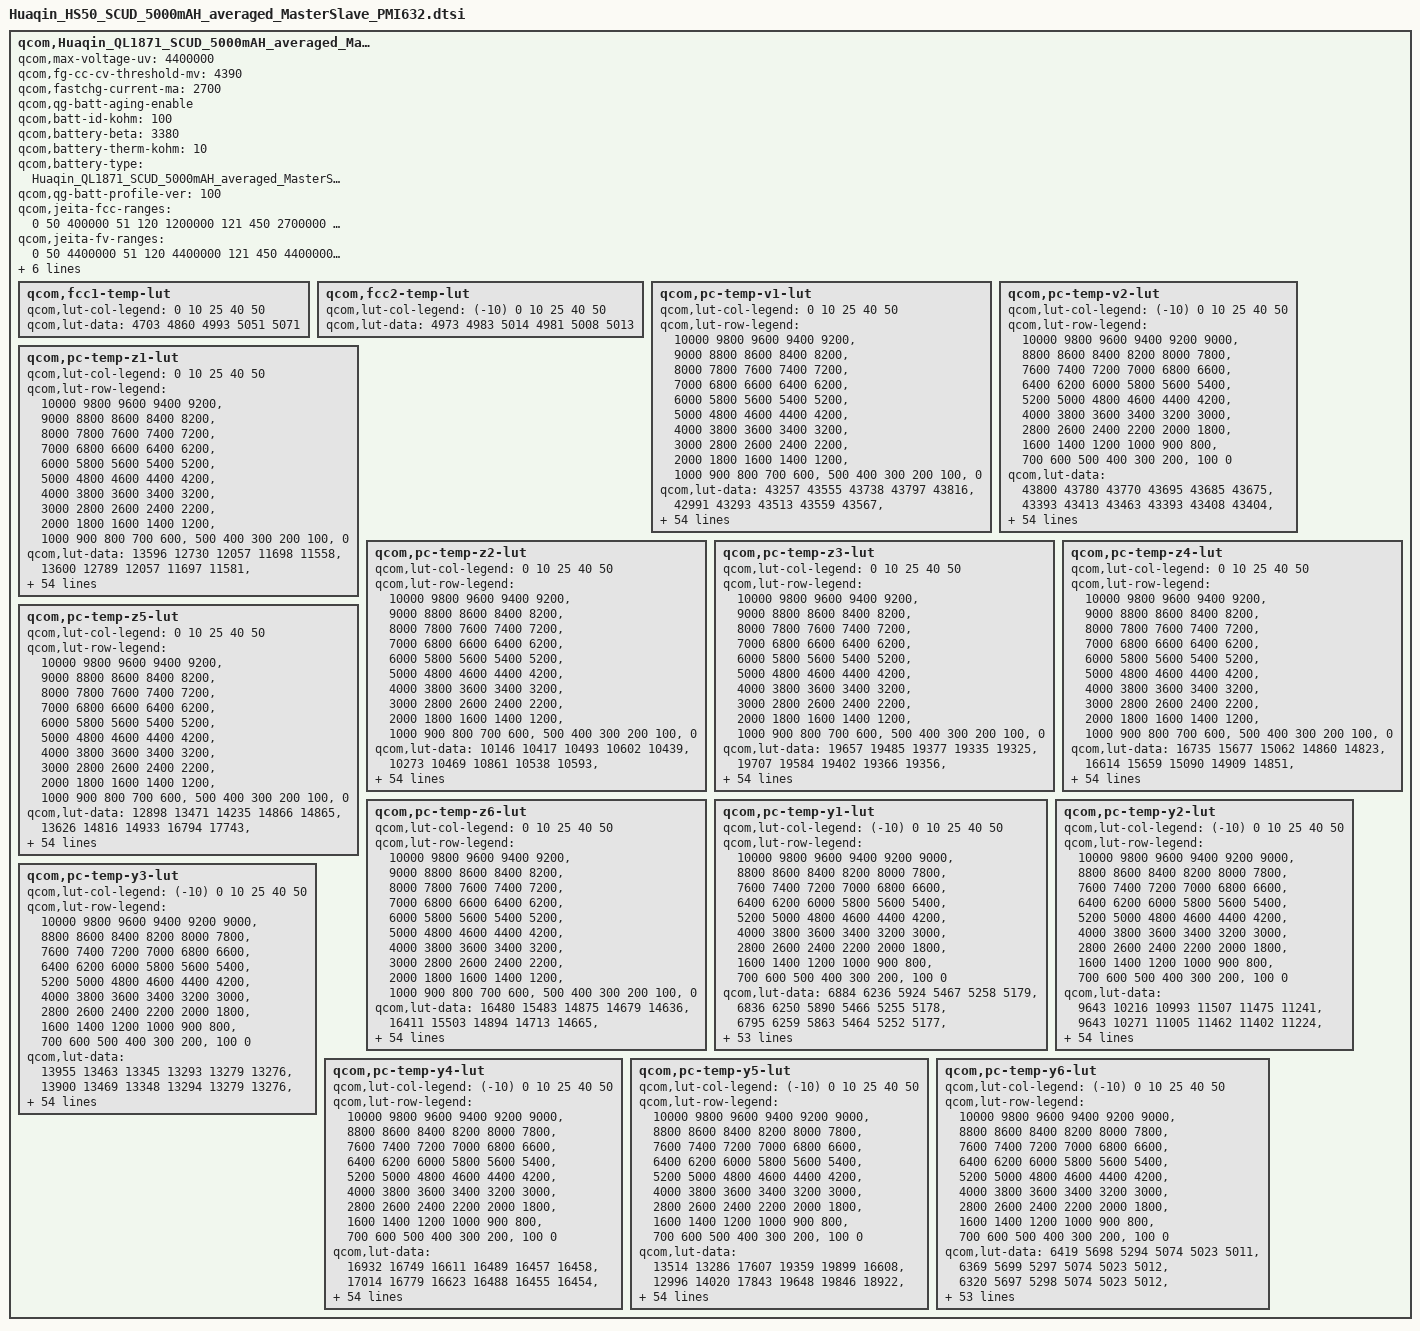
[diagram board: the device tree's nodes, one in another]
qcom,Huaqin_QL1871_SCUD_5000mAH_averaged_MasterSlave_PMI632 {
        /* Huaqin_QL1871_SCUD_5000mAH_averaged_MasterSlave_PMI632 */
	qcom,max-voltage-uv = <4400000>;
	qcom,fg-cc-cv-threshold-mv = <4390>;
	qcom,fastchg-current-ma = <2700>;
	/* HS60 add for SR-ZQL1695-01-357 Import battery aging by gaochao at 2019/08/29 start */
	qcom,qg-batt-aging-enable;
	/* HS60 add for SR-ZQL1695-01-357 Import battery aging by gaochao at 2019/08/29 end */
	qcom,batt-id-kohm = <100>;
	qcom,battery-beta = <3380>;
	qcom,battery-therm-kohm = <10>;
	qcom,battery-type = "Huaqin_QL1871_SCUD_5000mAH_averaged_MasterSlave_PMI632";
	qcom,qg-batt-profile-ver = <100>;

	qcom,jeita-fcc-ranges = <0   50   400000
				 51   120   1200000
				 121 450  2700000
				 451 500  2200000>;
	qcom,jeita-fv-ranges =  <0   50  4400000
				 51   120  4400000
				 121 450  4400000
				 451 500  4200000>;

	/* HS60 add for SR-ZQL1695-01-357 Import battery aging by gaochao at 2019/08/29 start */
	qcom,vfloat-ranges = <0 299 4400000
	                      300 399 4380000
                              400 699 4360000
                              700 999 4340000
                              1000 9999 4290000>;

	qcom,vbat-rechg-ranges = <0 299 4330000
                                  300 399 4310000
                                  400 699 4290000
                                  700 999 4270000
                                  1000 9999 4220000>;
	/* HS60 add for SR-ZQL1695-01-357 Import battery aging by gaochao at 2019/08/29 end */

	/* COOL = 15 DegC, WARM = 45 DegC */
	qcom,jeita-soft-thresholds = <0x2554 0xFDC>;
	/* COLD = 0 DegC, HOT = 50 DegC */
	/* Huaqin add for HS70-733 modify jeita-hard-thresholds to 50 by qianyingdong at 2019/11/26 start */
	qcom,jeita-hard-thresholds = <0x36B9 0xDBF>;
	/* Huaqin add for HS70-733 modify jeita-hard-thresholds to 50 by qianyingdong at 2019/11/26 end */

	qcom,fcc1-temp-lut {
		qcom,lut-col-legend = <0 10 25 40 50>;
		qcom,lut-data = <4703 4860 4993 5051 5071>;
	};

	qcom,fcc2-temp-lut {
		qcom,lut-col-legend = <(-10) 0 10 25 40 50>;
		qcom,lut-data = <4973 4983 5014 4981 5008 5013>;
	};

	qcom,pc-temp-v1-lut {
		qcom,lut-col-legend = <0 10 25 40 50>;
		qcom,lut-row-legend = <10000 9800 9600 9400 9200>,
			<9000 8800 8600 8400 8200>,
			<8000 7800 7600 7400 7200>,
			<7000 6800 6600 6400 6200>,
			<6000 5800 5600 5400 5200>,
			<5000 4800 4600 4400 4200>,
			<4000 3800 3600 3400 3200>,
			<3000 2800 2600 2400 2200>,
			<2000 1800 1600 1400 1200>,
			<1000 900 800 700 600>,
			<500 400 300 200 100>,
			<0>;
		qcom,lut-data = <43257 43555 43738 43797 43816>,
			<42991 43293 43513 43559 43567>,
			<42736 43047 43266 43323 43335>,
			<42494 42810 43023 43088 43107>,
			<42261 42576 42784 42856 42875>,
			<42036 42342 42544 42624 42643>,
			<41817 42111 42305 42390 42411>,
			<41605 41888 42067 42152 42179>,
			<41407 41669 41838 41919 41950>,
			<41223 41457 41615 41692 41721>,
			<41034 41258 41398 41470 41494>,
			<40822 41063 41185 41251 41273>,
			<40598 40856 40976 41036 41057>,
			<40386 40640 40771 40829 40848>,
			<40181 40433 40565 40627 40645>,
			<39990 40247 40369 40433 40449>,
			<39834 40075 40189 40246 40261>,
			<39707 39915 40019 40067 40081>,
			<39586 39766 39858 39896 39909>,
			<39460 39621 39712 39745 39755>,
			<39336 39478 39553 39589 39599>,
			<39219 39336 39357 39373 39393>,
			<39107 39183 39142 39097 39123>,
			<39000 39006 38937 38888 38908>,
			<38899 38834 38733 38757 38777>,
			<38803 38687 38587 38652 38672>,
			<38714 38549 38510 38555 38570>,
			<38628 38448 38452 38467 38474>,
			<38548 38381 38390 38385 38384>,
			<38479 38330 38327 38308 38298>,
			<38421 38291 38270 38238 38219>,
			<38370 38261 38219 38173 38150>,
			<38325 38232 38172 38114 38089>,
			<38286 38204 38128 38058 38030>,
			<38248 38177 38088 38008 37977>,
			<38212 38147 38048 37960 37924>,
			<38175 38116 38009 37912 37869>,
			<38129 38078 37967 37863 37811>,
			<38063 38016 37905 37798 37740>,
			<37983 37927 37811 37709 37645>,
			<37885 37826 37704 37606 37538>,
			<37761 37704 37595 37495 37425>,
			<37621 37566 37469 37368 37299>,
			<37465 37403 37304 37208 37141>,
			<37330 37261 37158 37070 37007>,
			<37231 37162 37068 36981 36923>,
			<37199 37133 37041 36954 36897>,
			<37168 37107 37023 36936 36878>,
			<37137 37081 37003 36916 36857>,
			<37074 37032 36953 36859 36793>,
			<36859 36808 36712 36601 36515>,
			<36413 36362 36274 36159 36070>,
			<35838 35785 35695 35581 35489>,
			<35060 34999 34907 34793 34697>,
			<33813 33756 33673 33560 33462>,
			<30000 30000 30000 30000 30000>;
	};

	qcom,pc-temp-v2-lut {
		qcom,lut-col-legend = <(-10) 0 10 25 40 50>;
		qcom,lut-row-legend = <10000 9800 9600 9400 9200 9000>,
			<8800 8600 8400 8200 8000 7800>,
			<7600 7400 7200 7000 6800 6600>,
			<6400 6200 6000 5800 5600 5400>,
			<5200 5000 4800 4600 4400 4200>,
			<4000 3800 3600 3400 3200 3000>,
			<2800 2600 2400 2200 2000 1800>,
			<1600 1400 1200 1000 900 800>,
			<700 600 500 400 300 200>,
			<100 0>;
		qcom,lut-data = <43800 43780 43770 43695 43685 43675>,
			<43393 43413 43463 43393 43408 43404>,
			<43026 43080 43174 43111 43143 43143>,
			<42703 42788 42906 42851 42892 42895>,
			<42414 42530 42657 42612 42656 42660>,
			<42163 42284 42416 42379 42422 42428>,
			<41962 42039 42175 42145 42189 42195>,
			<41780 41798 41939 41914 41957 41964>,
			<41556 41554 41708 41688 41730 41736>,
			<41274 41296 41482 41465 41505 41510>,
			<41026 41081 41263 41246 41284 41288>,
			<40878 40948 41055 41034 41067 41071>,
			<40752 40833 40854 40827 40854 40858>,
			<40529 40637 40650 40623 40650 40653>,
			<40103 40291 40445 40419 40451 40452>,
			<39714 39970 40239 40224 40261 40260>,
			<39500 39763 40030 40047 40078 40078>,
			<39334 39589 39822 39879 39901 39903>,
			<39165 39403 39611 39713 39734 39736>,
			<38992 39209 39396 39555 39580 39581>,
			<38829 39023 39192 39382 39408 39409>,
			<38675 38851 39003 39153 39179 39182>,
			<38530 38689 38829 38902 38937 38945>,
			<38411 38532 38677 38716 38756 38765>,
			<38310 38372 38542 38578 38611 38618>,
			<38224 38242 38421 38461 38487 38491>,
			<38151 38159 38312 38356 38379 38382>,
			<38087 38094 38211 38263 38283 38285>,
			<38027 38037 38114 38176 38195 38195>,
			<37969 37986 38019 38093 38114 38113>,
			<37914 37939 37945 38018 38042 38039>,
			<37860 37893 37890 37950 37978 37972>,
			<37807 37849 37843 37889 37919 37911>,
			<37752 37803 37801 37831 37856 37845>,
			<37695 37758 37765 37778 37791 37778>,
			<37637 37710 37727 37724 37718 37698>,
			<37575 37658 37688 37667 37628 37594>,
			<37509 37603 37645 37606 37533 37481>,
			<37444 37538 37589 37539 37449 37390>,
			<37380 37465 37520 37467 37374 37312>,
			<37313 37381 37439 37385 37293 37230>,
			<37243 37277 37339 37285 37198 37136>,
			<37169 37162 37215 37167 37089 37028>,
			<37094 37048 37058 37028 36955 36896>,
			<37008 36945 36918 36907 36845 36788>,
			<36904 36859 36829 36844 36798 36748>,
			<36845 36817 36800 36831 36785 36737>,
			<36773 36778 36771 36811 36769 36724>,
			<36683 36734 36731 36781 36743 36696>,
			<36553 36642 36652 36716 36656 36591>,
			<36326 36440 36435 36461 36353 36263>,
			<35957 36042 35985 35980 35857 35766>,
			<35404 35442 35358 35366 35215 35115>,
			<34583 34592 34492 34531 34330 34220>,
			<33186 33262 33142 33199 33033 32906>,
			<28507 28492 27834 27859 27906 27907>;
	};

	qcom,pc-temp-z1-lut {
		qcom,lut-col-legend = <0 10 25 40 50>;
		qcom,lut-row-legend = <10000 9800 9600 9400 9200>,
			<9000 8800 8600 8400 8200>,
			<8000 7800 7600 7400 7200>,
			<7000 6800 6600 6400 6200>,
			<6000 5800 5600 5400 5200>,
			<5000 4800 4600 4400 4200>,
			<4000 3800 3600 3400 3200>,
			<3000 2800 2600 2400 2200>,
			<2000 1800 1600 1400 1200>,
			<1000 900 800 700 600>,
			<500 400 300 200 100>,
			<0>;
		qcom,lut-data = <13596 12730 12057 11698 11558>,
			<13600 12789 12057 11697 11581>,
			<13602 12784 12050 11695 11579>,
			<13615 12766 12042 11692 11577>,
			<13638 12753 12030 11686 11575>,
			<13641 12745 12019 11678 11573>,
			<13609 12737 12011 11673 11571>,
			<13573 12722 12004 11668 11569>,
			<13568 12698 11997 11666 11569>,
			<13579 12683 11988 11666 11569>,
			<13581 12680 11984 11666 11570>,
			<13536 12678 11984 11665 11571>,
			<13456 12664 11983 11664 11571>,
			<13410 12620 11982 11664 11571>,
			<13387 12588 11978 11664 11571>,
			<13372 12583 11977 11663 11572>,
			<13367 12581 11978 11664 11573>,
			<13364 12582 11981 11666 11574>,
			<13362 12597 11984 11668 11575>,
			<13356 12612 11989 11669 11577>,
			<13343 12618 11994 11670 11578>,
			<13333 12625 11996 11671 11579>,
			<13321 12628 11999 11672 11579>,
			<13310 12634 12003 11674 11580>,
			<13310 12642 12008 11677 11582>,
			<13316 12651 12013 11680 11584>,
			<13323 12661 12017 11684 11586>,
			<13328 12667 12021 11687 11590>,
			<13336 12665 12024 11691 11593>,
			<13337 12661 12028 11695 11596>,
			<13331 12663 12032 11698 11599>,
			<13325 12668 12036 11702 11602>,
			<13321 12674 12041 11706 11606>,
			<13317 12680 12048 11711 11609>,
			<13317 12686 12058 11716 11613>,
			<13323 12691 12067 11721 11617>,
			<13332 12693 12073 11725 11621>,
			<13344 12697 12080 11730 11625>,
			<13366 12714 12083 11735 11629>,
			<13392 12746 12086 11740 11632>,
			<13412 12764 12090 11746 11635>,
			<13429 12773 12099 11750 11638>,
			<13438 12776 12109 11754 11642>,
			<13442 12778 12116 11758 11646>,
			<13495 12791 12123 11763 11650>,
			<13449 12771 12138 11770 11650>,
			<13424 12765 12134 11767 11651>,
			<13409 12762 12132 11770 11653>,
			<13429 12765 12143 11775 11657>,
			<13463 12779 12145 11781 11661>,
			<13453 12811 12160 11790 11667>,
			<13475 12793 12171 11799 11673>,
			<13489 12839 12184 11813 11685>,
			<13470 12883 12213 11829 11701>,
			<13470 12883 12213 11829 11701>,
			<13470 12883 12213 11829 11701>;
	};

	qcom,pc-temp-z2-lut {
		qcom,lut-col-legend = <0 10 25 40 50>;
		qcom,lut-row-legend = <10000 9800 9600 9400 9200>,
			<9000 8800 8600 8400 8200>,
			<8000 7800 7600 7400 7200>,
			<7000 6800 6600 6400 6200>,
			<6000 5800 5600 5400 5200>,
			<5000 4800 4600 4400 4200>,
			<4000 3800 3600 3400 3200>,
			<3000 2800 2600 2400 2200>,
			<2000 1800 1600 1400 1200>,
			<1000 900 800 700 600>,
			<500 400 300 200 100>,
			<0>;
		qcom,lut-data = <10146 10417 10493 10602 10439>,
			<10273 10469 10861 10538 10593>,
			<10347 10465 11439 10634 10657>,
			<10358 10447 11580 10726 10685>,
			<10351 10432 11382 10903 10652>,
			<10350 10419 11129 11247 10592>,
			<10354 10408 10874 11325 10564>,
			<10359 10398 10611 10926 10540>,
			<10358 10390 10546 10576 10524>,
			<10350 10385 10685 10762 10517>,
			<10339 10377 10831 11180 10510>,
			<10328 10364 10874 11295 10489>,
			<10315 10353 10903 11265 10414>,
			<10304 10341 10893 11234 10365>,
			<10290 10334 10719 11234 10368>,
			<10276 10413 10576 11255 10376>,
			<10270 10558 10585 11199 10388>,
			<10272 10595 10602 10801 10405>,
			<10273 10501 10619 10531 10423>,
			<10267 10417 10636 10523 10442>,
			<10254 10425 10659 10519 10464>,
			<10244 10443 10705 10553 10513>,
			<10237 10461 10753 10660 10612>,
			<10234 10480 10753 10703 10655>,
			<10235 10495 10703 10598 10592>,
			<10239 10499 10665 10484 10523>,
			<10247 10501 10658 10492 10545>,
			<10261 10503 10655 10548 10636>,
			<10281 10506 10663 10594 10702>,
			<10304 10510 10701 10630 10722>,
			<10334 10513 10723 10658 10705>,
			<10359 10521 10721 10667 10618>,
			<10338 10527 10717 10663 10473>,
			<10243 10530 10719 10659 10416>,
			<10185 10533 10726 10653 10425>,
			<10193 10538 10733 10654 10447>,
			<10203 10553 10740 10677 10476>,
			<10224 10570 10749 10717 10520>,
			<10326 10582 10768 10747 10557>,
			<10436 10595 10818 10770 10589>,
			<10463 10607 10847 10790 10615>,
			<10476 10618 10838 10803 10636>,
			<10513 10632 10829 10813 10653>,
			<10592 10649 10844 10818 10641>,
			<10370 10859 10885 10790 10650>,
			<10343 10940 10947 10753 10659>,
			<10168 11066 10920 10762 10646>,
			<10089 11178 10944 10789 10671>,
			<10114 11349 10980 10782 10707>,
			<10443 11538 11045 10858 10852>,
			<11180 11349 11098 10886 10674>,
			<9963 11262 11120 10703 10469>,
			<9831 11128 11137 10652 10408>,
			<9669 10919 11087 11428 10344>,
			<9669 10919 11087 11428 10344>,
			<9669 10919 11087 11428 10344>;
	};

	qcom,pc-temp-z3-lut {
		qcom,lut-col-legend = <0 10 25 40 50>;
		qcom,lut-row-legend = <10000 9800 9600 9400 9200>,
			<9000 8800 8600 8400 8200>,
			<8000 7800 7600 7400 7200>,
			<7000 6800 6600 6400 6200>,
			<6000 5800 5600 5400 5200>,
			<5000 4800 4600 4400 4200>,
			<4000 3800 3600 3400 3200>,
			<3000 2800 2600 2400 2200>,
			<2000 1800 1600 1400 1200>,
			<1000 900 800 700 600>,
			<500 400 300 200 100>,
			<0>;
		qcom,lut-data = <19657 19485 19377 19335 19325>,
			<19707 19584 19402 19366 19356>,
			<19731 19610 19431 19385 19368>,
			<19723 19623 19447 19395 19374>,
			<19689 19630 19463 19402 19379>,
			<19666 19632 19472 19408 19383>,
			<19664 19632 19470 19412 19385>,
			<19665 19626 19465 19409 19384>,
			<19665 19614 19464 19405 19383>,
			<19667 19604 19469 19405 19382>,
			<19668 19599 19473 19408 19380>,
			<19669 19594 19467 19408 19376>,
			<19672 19589 19459 19403 19371>,
			<19674 19582 19451 19397 19366>,
			<19671 19575 19439 19391 19363>,
			<19665 19567 19427 19385 19359>,
			<19657 19557 19420 19380 19356>,
			<19635 19546 19413 19370 19353>,
			<19615 19533 19410 19363 19350>,
			<19610 19525 19407 19357 19345>,
			<19610 19526 19405 19352 19341>,
			<19612 19530 19415 19356 19342>,
			<19616 19534 19430 19368 19349>,
			<19621 19543 19432 19373 19352>,
			<19622 19550 19428 19361 19340>,
			<19621 19552 19424 19347 19325>,
			<19618 19553 19418 19345 19325>,
			<19612 19554 19413 19346 19337>,
			<19606 19552 19413 19348 19345>,
			<19598 19549 19415 19355 19355>,
			<19585 19545 19417 19363 19366>,
			<19569 19540 19419 19368 19366>,
			<19551 19535 19420 19373 19364>,
			<19532 19531 19421 19374 19361>,
			<19515 19527 19420 19372 19355>,
			<19499 19523 19420 19369 19348>,
			<19485 19519 19417 19365 19344>,
			<19482 19515 19413 19359 19340>,
			<19538 19512 19411 19356 19337>,
			<19598 19510 19410 19354 19336>,
			<19601 19506 19409 19352 19335>,
			<19594 19502 19404 19350 19336>,
			<19582 19495 19398 19348 19337>,
			<19555 19485 19396 19349 19340>,
			<19387 19445 19387 19345 19338>,
			<19326 19427 19375 19338 19331>,
			<19273 19398 19373 19336 19324>,
			<19264 19374 19363 19331 19321>,
			<19265 19340 19348 19330 19318>,
			<19264 19318 19348 19324 19311>,
			<19262 19346 19341 19325 19329>,
			<19266 19323 19333 19336 19341>,
			<19267 19318 19328 19340 19344>,
			<19271 19318 19320 19297 19341>,
			<19271 19318 19320 19297 19341>,
			<19271 19318 19320 19297 19341>;
	};

	qcom,pc-temp-z4-lut {
		qcom,lut-col-legend = <0 10 25 40 50>;
		qcom,lut-row-legend = <10000 9800 9600 9400 9200>,
			<9000 8800 8600 8400 8200>,
			<8000 7800 7600 7400 7200>,
			<7000 6800 6600 6400 6200>,
			<6000 5800 5600 5400 5200>,
			<5000 4800 4600 4400 4200>,
			<4000 3800 3600 3400 3200>,
			<3000 2800 2600 2400 2200>,
			<2000 1800 1600 1400 1200>,
			<1000 900 800 700 600>,
			<500 400 300 200 100>,
			<0>;
		qcom,lut-data = <16735 15677 15062 14860 14823>,
			<16614 15659 15090 14909 14851>,
			<16477 15567 15040 14886 14838>,
			<16309 15377 14983 14855 14819>,
			<16110 15231 14912 14818 14800>,
			<15938 15134 14856 14778 14778>,
			<15789 15056 14827 14757 14760>,
			<15656 14997 14805 14744 14745>,
			<15546 14951 14780 14735 14730>,
			<15453 14910 14745 14716 14716>,
			<15371 14873 14715 14686 14704>,
			<15294 14841 14699 14673 14697>,
			<15224 14812 14688 14668 14693>,
			<15168 14787 14682 14665 14689>,
			<15125 14767 14689 14662 14684>,
			<15090 14747 14696 14658 14679>,
			<15064 14730 14693 14656 14674>,
			<15044 14723 14688 14661 14669>,
			<15028 14722 14683 14664 14664>,
			<15012 14721 14676 14661 14659>,
			<14990 14714 14672 14659 14655>,
			<14969 14704 14683 14677 14669>,
			<14945 14702 14708 14739 14733>,
			<14923 14721 14739 14777 14776>,
			<14910 14743 14788 14789 14786>,
			<14900 14759 14813 14795 14792>,
			<14896 14783 14804 14791 14786>,
			<14896 14793 14785 14776 14761>,
			<14897 14788 14768 14759 14736>,
			<14899 14777 14754 14739 14714>,
			<14902 14766 14739 14720 14694>,
			<14906 14752 14726 14703 14683>,
			<14913 14739 14713 14687 14674>,
			<14925 14727 14703 14678 14670>,
			<14930 14717 14695 14673 14667>,
			<14929 14708 14689 14670 14665>,
			<14928 14699 14685 14670 14665>,
			<14920 14693 14682 14671 14666>,
			<14835 14691 14683 14673 14669>,
			<14744 14691 14689 14682 14679>,
			<14729 14690 14693 14690 14689>,
			<14724 14688 14688 14686 14684>,
			<14722 14686 14681 14680 14677>,
			<14724 14684 14678 14680 14678>,
			<14815 14675 14667 14673 14672>,
			<14870 14672 14653 14659 14657>,
			<14923 14696 14647 14652 14655>,
			<14926 14716 14645 14643 14644>,
			<14918 14748 14651 14627 14627>,
			<14910 14767 14648 14630 14628>,
			<14908 14739 14671 14657 14646>,
			<14929 14782 14690 14655 14644>,
			<14942 14795 14698 14654 14645>,
			<14956 14806 14712 14703 14650>,
			<14956 14806 14712 14703 14650>,
			<14956 14806 14712 14703 14650>;
	};

	qcom,pc-temp-z5-lut {
		qcom,lut-col-legend = <0 10 25 40 50>;
		qcom,lut-row-legend = <10000 9800 9600 9400 9200>,
			<9000 8800 8600 8400 8200>,
			<8000 7800 7600 7400 7200>,
			<7000 6800 6600 6400 6200>,
			<6000 5800 5600 5400 5200>,
			<5000 4800 4600 4400 4200>,
			<4000 3800 3600 3400 3200>,
			<3000 2800 2600 2400 2200>,
			<2000 1800 1600 1400 1200>,
			<1000 900 800 700 600>,
			<500 400 300 200 100>,
			<0>;
		qcom,lut-data = <12898 13471 14235 14866 14865>,
			<13626 14816 14933 16794 17743>,
			<14213 15430 15930 18368 19153>,
			<14603 15825 16658 19390 19932>,
			<14930 16285 17639 20272 20548>,
			<15262 16908 18668 21138 21176>,
			<15675 17481 19402 21716 21712>,
			<16116 17820 20081 22391 22106>,
			<16488 18050 21169 22615 22521>,
			<16808 18369 23303 25229 23500>,
			<17106 19000 25578 30597 24735>,
			<17430 19811 27880 32238 25171>,
			<17739 20692 30189 32206 25082>,
			<17904 22011 30710 31927 24993>,
			<18054 22883 28323 32357 25287>,
			<18190 22155 26097 33509 25966>,
			<18125 20608 25844 33557 26820>,
			<17622 20314 25626 30370 27994>,
			<17118 21900 25841 27931 29014>,
			<16961 24035 27104 27916 29741>,
			<17030 26546 29367 28055 30389>,
			<17241 30662 41029 32085 32034>,
			<17960 36098 57331 42478 36136>,
			<19173 46152 59297 45968 37484>,
			<20552 55095 50565 35328 29648>,
			<22196 57398 41473 23384 19810>,
			<23949 57558 35278 20945 18039>,
			<26042 56296 30405 19911 18995>,
			<28245 53671 29297 19716 20690>,
			<28881 50557 29302 20841 23367>,
			<28100 47797 29731 22780 26327>,
			<26902 44916 31199 25437 28424>,
			<25742 42907 33709 29436 30259>,
			<24487 41779 36586 32876 31527>,
			<23210 40953 40528 36483 32152>,
			<21768 40813 43124 38658 32229>,
			<20270 41057 43860 38294 31997>,
			<19670 41470 44131 37098 31561>,
			<22476 42535 43956 35606 30904>,
			<25851 44228 43563 33174 29063>,
			<26839 44611 42874 30634 27181>,
			<27653 41699 38688 28386 26162>,
			<27818 38361 34409 26789 25556>,
			<25862 35563 34171 26978 26533>,
			<18362 30712 34638 26801 26702>,
			<14014 26928 31884 25474 24288>,
			<11887 19094 31290 24612 21424>,
			<11750 16348 26357 24133 22298>,
			<11750 14546 20830 28069 25841>,
			<11792 13513 21442 24869 22532>,
			<11845 15763 18817 19573 22676>,
			<11838 13376 16089 19850 23367>,
			<11717 12978 15114 19803 22374>,
			<11622 12700 14136 14189 19162>,
			<11622 12700 14136 14189 19162>,
			<11622 12700 14136 14189 19162>;
	};

	qcom,pc-temp-z6-lut {
		qcom,lut-col-legend = <0 10 25 40 50>;
		qcom,lut-row-legend = <10000 9800 9600 9400 9200>,
			<9000 8800 8600 8400 8200>,
			<8000 7800 7600 7400 7200>,
			<7000 6800 6600 6400 6200>,
			<6000 5800 5600 5400 5200>,
			<5000 4800 4600 4400 4200>,
			<4000 3800 3600 3400 3200>,
			<3000 2800 2600 2400 2200>,
			<2000 1800 1600 1400 1200>,
			<1000 900 800 700 600>,
			<500 400 300 200 100>,
			<0>;
		qcom,lut-data = <16480 15483 14875 14679 14636>,
			<16411 15503 14894 14713 14665>,
			<16327 15467 14886 14712 14665>,
			<16219 15370 14871 14709 14664>,
			<16090 15292 14844 14699 14659>,
			<15982 15240 14820 14684 14651>,
			<15899 15195 14802 14674 14644>,
			<15828 15155 14787 14667 14638>,
			<15768 15120 14773 14660 14631>,
			<15718 15090 14759 14651 14624>,
			<15670 15067 14747 14642 14618>,
			<15618 15046 14736 14635 14612>,
			<15564 15023 14726 14630 14608>,
			<15521 14996 14719 14625 14604>,
			<15489 14975 14714 14620 14599>,
			<15462 14959 14709 14615 14595>,
			<15438 14946 14704 14612 14591>,
			<15415 14940 14699 14608 14587>,
			<15396 14935 14696 14605 14583>,
			<15382 14932 14692 14600 14578>,
			<15371 14932 14691 14597 14575>,
			<15361 14932 14700 14607 14582>,
			<15352 14933 14719 14642 14614>,
			<15343 14946 14737 14658 14632>,
			<15337 14962 14756 14657 14630>,
			<15332 14972 14764 14655 14627>,
			<15328 14985 14759 14652 14623>,
			<15325 14991 14749 14647 14619>,
			<15323 14988 14743 14642 14615>,
			<15319 14983 14739 14638 14612>,
			<15313 14978 14735 14634 14609>,
			<15307 14971 14731 14630 14605>,
			<15303 14965 14727 14627 14601>,
			<15299 14960 14725 14624 14597>,
			<15295 14955 14722 14622 14593>,
			<15292 14952 14721 14619 14590>,
			<15289 14950 14719 14617 14587>,
			<15288 14948 14718 14615 14586>,
			<15291 14950 14718 14615 14586>,
			<15296 14953 14723 14618 14590>,
			<15300 14956 14726 14621 14594>,
			<15303 14957 14722 14619 14593>,
			<15304 14957 14719 14616 14591>,
			<15301 14958 14719 14618 14593>,
			<15267 14944 14714 14614 14590>,
			<15261 14936 14704 14605 14580>,
			<15258 14932 14701 14601 14576>,
			<15256 14929 14696 14594 14569>,
			<15255 14928 14692 14588 14561>,
			<15258 14927 14694 14587 14559>,
			<15264 14938 14703 14600 14577>,
			<15282 14954 14711 14608 14585>,
			<15300 14966 14718 14613 14589>,
			<15325 14987 14728 14617 14594>,
			<15325 14987 14728 14617 14594>,
			<15325 14987 14728 14617 14594>;
	};

	qcom,pc-temp-y1-lut {
		qcom,lut-col-legend = <(-10) 0 10 25 40 50>;
		qcom,lut-row-legend = <10000 9800 9600 9400 9200 9000>,
			<8800 8600 8400 8200 8000 7800>,
			<7600 7400 7200 7000 6800 6600>,
			<6400 6200 6000 5800 5600 5400>,
			<5200 5000 4800 4600 4400 4200>,
			<4000 3800 3600 3400 3200 3000>,
			<2800 2600 2400 2200 2000 1800>,
			<1600 1400 1200 1000 900 800>,
			<700 600 500 400 300 200>,
			<100 0>;
		qcom,lut-data = <6884 6236 5924 5467 5258 5179>,
			<6836 6250 5890 5466 5255 5178>,
			<6795 6259 5863 5464 5252 5177>,
			<6762 6263 5844 5461 5248 5176>,
			<6741 6264 5832 5459 5245 5175>,
			<6733 6262 5828 5457 5243 5174>,
			<6743 6254 5836 5455 5241 5172>,
			<6760 6245 5848 5453 5239 5171>,
			<6763 6245 5849 5452 5238 5170>,
			<6753 6257 5840 5451 5236 5170>,
			<6747 6264 5833 5450 5234 5169>,
			<6764 6258 5830 5449 5233 5169>,
			<6795 6250 5828 5447 5232 5169>,
			<6801 6249 5826 5446 5232 5169>,
			<6779 6253 5823 5443 5233 5169>,
			<6763 6253 5821 5441 5233 5169>,
			<6775 6247 5831 5441 5233 5169>,
			<6796 6239 5845 5441 5233 5169>,
			<6796 6233 5847 5442 5232 5170>,
			<6775 6226 5843 5445 5232 5170>,
			<6758 6222 5840 5448 5232 5171>,
			<6753 6233 5840 5450 5234 5172>,
			<6746 6254 5841 5453 5236 5173>,
			<6745 6262 5845 5455 5238 5173>,
			<6761 6263 5852 5456 5239 5175>,
			<6774 6265 5854 5458 5241 5176>,
			<6774 6268 5852 5462 5243 5178>,
			<6772 6270 5848 5467 5246 5181>,
			<6768 6270 5848 5470 5248 5182>,
			<6755 6268 5851 5472 5251 5184>,
			<6744 6267 5853 5474 5253 5186>,
			<6743 6263 5846 5478 5256 5187>,
			<6743 6256 5836 5484 5259 5188>,
			<6743 6249 5841 5489 5262 5190>,
			<6742 6241 5864 5495 5265 5193>,
			<6740 6237 5876 5500 5268 5196>,
			<6726 6236 5871 5504 5270 5197>,
			<6700 6235 5865 5509 5272 5198>,
			<6694 6237 5865 5513 5274 5199>,
			<6712 6250 5873 5516 5277 5201>,
			<6729 6260 5879 5518 5279 5202>,
			<6732 6264 5877 5518 5281 5205>,
			<6725 6268 5872 5517 5283 5208>,
			<6701 6243 5860 5526 5286 5209>,
			<6695 6225 5885 5539 5292 5212>,
			<6743 6280 5884 5552 5298 5215>,
			<6761 6288 5882 5544 5300 5218>,
			<6763 6245 5873 5555 5300 5217>,
			<6784 6274 5874 5549 5300 5217>,
			<6771 6248 5879 5566 5299 5218>,
			<6764 6269 5880 5572 5303 5220>,
			<6787 6264 5897 5576 5310 5225>,
			<6819 6287 5893 5589 5322 5233>,
			<6854 6323 5929 5609 5336 5245>,
			<6854 6323 5929 5609 5336 5245>,
			<6854 6323 5929 5609 5336 5245>;
	};

	qcom,pc-temp-y2-lut {
		qcom,lut-col-legend = <(-10) 0 10 25 40 50>;
		qcom,lut-row-legend = <10000 9800 9600 9400 9200 9000>,
			<8800 8600 8400 8200 8000 7800>,
			<7600 7400 7200 7000 6800 6600>,
			<6400 6200 6000 5800 5600 5400>,
			<5200 5000 4800 4600 4400 4200>,
			<4000 3800 3600 3400 3200 3000>,
			<2800 2600 2400 2200 2000 1800>,
			<1600 1400 1200 1000 900 800>,
			<700 600 500 400 300 200>,
			<100 0>;
		qcom,lut-data = <9643 10216 10993 11507 11475 11241>,
			<9643 10271 11005 11462 11402 11224>,
			<9643 10353 11011 11419 11323 11202>,
			<9734 10438 11012 11379 11250 11179>,
			<9842 10506 11011 11342 11195 11157>,
			<9934 10535 11008 11309 11171 11139>,
			<10135 10529 10995 11276 11178 11116>,
			<10403 10518 10979 11249 11194 11090>,
			<10462 10548 10977 11237 11188 11074>,
			<10301 10727 10982 11236 11158 11054>,
			<10181 10854 10990 11237 11134 11045>,
			<10338 10860 11011 11230 11138 11054>,
			<10609 10862 11048 11217 11156 11067>,
			<10599 10873 11094 11218 11163 11062>,
			<10086 10915 11163 11251 11178 11023>,
			<9701 10964 11215 11294 11197 10998>,
			<9691 11013 11242 11337 11234 11031>,
			<9687 11062 11259 11384 11297 11101>,
			<9685 11098 11258 11432 11370 11202>,
			<9683 11129 11243 11486 11472 11375>,
			<9682 11145 11233 11516 11522 11468>,
			<9679 11139 11259 11498 11479 11397>,
			<9676 11118 11304 11465 11415 11289>,
			<9675 10987 11330 11461 11399 11274>,
			<9675 10295 11348 11484 11402 11301>,
			<9674 9777 11360 11512 11408 11326>,
			<9673 9769 11369 11538 11426 11343>,
			<9672 9779 11377 11568 11445 11363>,
			<9670 9777 11393 11592 11454 11383>,
			<9669 9755 11423 11619 11471 11411>,
			<9668 9729 11435 11635 11498 11439>,
			<9667 9712 11417 11632 11569 11467>,
			<9666 9696 11390 11624 11648 11488>,
			<9665 9688 11374 11620 11659 11494>,
			<9664 9683 11362 11618 11644 11495>,
			<9664 9679 11345 11616 11625 11490>,
			<9663 9675 11311 11613 11590 11464>,
			<9663 9671 11260 11603 11555 11426>,
			<9662 9668 11208 11588 11542 11396>,
			<9662 9666 11151 11557 11523 11366>,
			<9661 9664 11083 11525 11510 11340>,
			<9661 9663 11001 11502 11509 11323>,
			<9661 9662 10827 11475 11508 11314>,
			<9660 9661 10340 11423 11508 11298>,
			<9660 9660 10045 11341 11427 11270>,
			<9659 9659 9806 11291 11327 11153>,
			<9659 9659 9771 11314 11321 11149>,
			<9659 9658 9727 11306 11378 11166>,
			<9658 9658 9700 11303 11408 11252>,
			<9658 9657 9688 11296 11386 11149>,
			<9658 9657 9680 11226 11312 11079>,
			<9657 9657 9671 11105 11270 10997>,
			<9657 9656 9665 11023 11186 10919>,
			<9655 9656 9660 10903 11010 10800>,
			<9655 9656 9660 10903 11010 10800>,
			<9655 9656 9660 10903 11010 10800>;
	};

	qcom,pc-temp-y3-lut {
		qcom,lut-col-legend = <(-10) 0 10 25 40 50>;
		qcom,lut-row-legend = <10000 9800 9600 9400 9200 9000>,
			<8800 8600 8400 8200 8000 7800>,
			<7600 7400 7200 7000 6800 6600>,
			<6400 6200 6000 5800 5600 5400>,
			<5200 5000 4800 4600 4400 4200>,
			<4000 3800 3600 3400 3200 3000>,
			<2800 2600 2400 2200 2000 1800>,
			<1600 1400 1200 1000 900 800>,
			<700 600 500 400 300 200>,
			<100 0>;
		qcom,lut-data = <13955 13463 13345 13293 13279 13276>,
			<13900 13469 13348 13294 13279 13276>,
			<13825 13472 13351 13295 13280 13277>,
			<13746 13473 13353 13296 13281 13278>,
			<13680 13473 13355 13297 13281 13279>,
			<13641 13472 13357 13297 13282 13280>,
			<13626 13470 13359 13297 13283 13280>,
			<13615 13467 13361 13297 13283 13280>,
			<13590 13461 13361 13297 13284 13281>,
			<13529 13450 13361 13298 13284 13281>,
			<13486 13440 13361 13299 13285 13282>,
			<13481 13429 13359 13302 13285 13282>,
			<13479 13418 13358 13304 13285 13283>,
			<13475 13413 13356 13304 13286 13283>,
			<13467 13410 13354 13304 13289 13283>,
			<13460 13408 13351 13304 13290 13283>,
			<13454 13402 13350 13303 13291 13285>,
			<13448 13394 13348 13303 13291 13286>,
			<13443 13386 13345 13303 13291 13287>,
			<13439 13378 13339 13304 13290 13288>,
			<13434 13371 13333 13305 13289 13288>,
			<13426 13366 13329 13302 13287 13285>,
			<13416 13360 13326 13296 13283 13280>,
			<13410 13347 13323 13293 13281 13278>,
			<13408 13306 13322 13291 13280 13277>,
			<13406 13277 13320 13289 13280 13277>,
			<13411 13274 13319 13290 13279 13276>,
			<13425 13273 13318 13291 13278 13276>,
			<13440 13274 13315 13292 13278 13276>,
			<13458 13278 13310 13291 13278 13275>,
			<13478 13285 13308 13290 13278 13275>,
			<13501 13300 13309 13290 13279 13275>,
			<13527 13323 13311 13291 13280 13275>,
			<13555 13340 13313 13291 13280 13276>,
			<13584 13355 13315 13291 13280 13277>,
			<13614 13372 13317 13291 13280 13278>,
			<13643 13394 13319 13291 13280 13277>,
			<13673 13422 13321 13291 13278 13275>,
			<13705 13453 13323 13290 13278 13275>,
			<13742 13490 13324 13290 13278 13276>,
			<13779 13529 13326 13290 13278 13276>,
			<13814 13568 13329 13291 13279 13277>,
			<13850 13610 13332 13291 13279 13277>,
			<13896 13656 13336 13292 13278 13276>,
			<13950 13714 13344 13293 13279 13276>,
			<13961 13733 13345 13293 13280 13280>,
			<13972 13756 13353 13297 13283 13283>,
			<14032 13813 13371 13299 13287 13286>,
			<14093 13864 13393 13303 13290 13288>,
			<14162 13911 13417 13308 13290 13286>,
			<14237 13967 13442 13304 13285 13283>,
			<14337 14037 13487 13305 13285 13283>,
			<14473 14142 13588 13314 13290 13286>,
			<14859 14276 13733 13323 13295 13292>,
			<14859 14276 13733 13323 13295 13292>,
			<14859 14276 13733 13323 13295 13292>;
	};

	qcom,pc-temp-y4-lut {
		qcom,lut-col-legend = <(-10) 0 10 25 40 50>;
		qcom,lut-row-legend = <10000 9800 9600 9400 9200 9000>,
			<8800 8600 8400 8200 8000 7800>,
			<7600 7400 7200 7000 6800 6600>,
			<6400 6200 6000 5800 5600 5400>,
			<5200 5000 4800 4600 4400 4200>,
			<4000 3800 3600 3400 3200 3000>,
			<2800 2600 2400 2200 2000 1800>,
			<1600 1400 1200 1000 900 800>,
			<700 600 500 400 300 200>,
			<100 0>;
		qcom,lut-data = <16932 16749 16611 16489 16457 16458>,
			<17014 16779 16623 16488 16455 16454>,
			<17072 16822 16643 16488 16454 16450>,
			<17108 16867 16663 16488 16454 16449>,
			<17126 16905 16679 16489 16454 16448>,
			<17132 16925 16685 16491 16454 16448>,
			<17107 16931 16683 16493 16455 16448>,
			<17065 16935 16681 16496 16457 16450>,
			<17072 16938 16681 16500 16459 16452>,
			<17175 16942 16685 16504 16463 16454>,
			<17248 16950 16692 16508 16467 16457>,
			<17247 17023 16709 16513 16471 16459>,
			<17242 17136 16732 16518 16476 16462>,
			<17210 17131 16750 16526 16480 16467>,
			<17036 16956 16769 16539 16484 16473>,
			<16902 16825 16777 16554 16489 16479>,
			<16891 16813 16762 16576 16499 16485>,
			<16886 16807 16734 16601 16512 16491>,
			<16874 16793 16704 16617 16532 16504>,
			<16843 16758 16666 16629 16564 16528>,
			<16811 16718 16630 16635 16580 16541>,
			<16785 16678 16597 16591 16546 16519>,
			<16762 16641 16569 16510 16490 16484>,
			<16754 16636 16553 16482 16468 16465>,
			<16754 16654 16543 16475 16456 16454>,
			<16754 16670 16535 16473 16451 16449>,
			<16751 16675 16528 16473 16454 16451>,
			<16749 16678 16521 16474 16458 16454>,
			<16747 16679 16515 16476 16464 16459>,
			<16745 16678 16507 16480 16471 16467>,
			<16743 16676 16502 16484 16479 16475>,
			<16743 16669 16501 16489 16490 16485>,
			<16742 16660 16501 16493 16499 16495>,
			<16742 16659 16504 16494 16500 16498>,
			<16745 16664 16514 16494 16500 16499>,
			<16749 16670 16525 16493 16498 16497>,
			<16755 16675 16541 16490 16482 16481>,
			<16762 16680 16558 16484 16462 16461>,
			<16770 16682 16571 16482 16459 16458>,
			<16778 16681 16582 16483 16461 16460>,
			<16787 16679 16587 16485 16463 16462>,
			<16801 16673 16588 16490 16466 16466>,
			<16821 16663 16588 16495 16468 16467>,
			<16839 16658 16585 16495 16458 16454>,
			<16850 16660 16586 16494 16449 16445>,
			<16813 16660 16588 16493 16455 16453>,
			<16795 16671 16603 16499 16466 16471>,
			<16816 16692 16625 16513 16488 16502>,
			<16826 16717 16656 16537 16522 16534>,
			<16833 16747 16699 16564 16529 16529>,
			<16826 16748 16708 16543 16476 16466>,
			<16814 16712 16676 16528 16463 16458>,
			<16814 16699 16681 16551 16471 16460>,
			<16907 16708 16706 16590 16497 16482>,
			<16907 16708 16706 16590 16497 16482>,
			<16907 16708 16706 16590 16497 16482>;
	};

	qcom,pc-temp-y5-lut {
		qcom,lut-col-legend = <(-10) 0 10 25 40 50>;
		qcom,lut-row-legend = <10000 9800 9600 9400 9200 9000>,
			<8800 8600 8400 8200 8000 7800>,
			<7600 7400 7200 7000 6800 6600>,
			<6400 6200 6000 5800 5600 5400>,
			<5200 5000 4800 4600 4400 4200>,
			<4000 3800 3600 3400 3200 3000>,
			<2800 2600 2400 2200 2000 1800>,
			<1600 1400 1200 1000 900 800>,
			<700 600 500 400 300 200>,
			<100 0>;
		qcom,lut-data = <13514 13286 17607 19359 19899 16608>,
			<12996 14020 17843 19648 19846 18922>,
			<12938 14878 18120 19670 19719 20448>,
			<13260 15720 18395 19484 19551 21332>,
			<13882 16408 18625 19150 19371 21723>,
			<14725 16804 18767 18726 19211 21767>,
			<17202 16973 18845 18053 18834 21172>,
			<20432 17042 18895 17246 18263 20156>,
			<20502 16814 18846 16755 17798 19480>,
			<16813 15874 18492 16396 17327 18751>,
			<14187 15261 18015 16232 16858 18131>,
			<16964 16513 17206 16273 16313 17723>,
			<21794 18735 16383 16337 15856 17355>,
			<22212 19868 16671 16259 15860 16820>,
			<17530 20924 18646 15709 16213 16057>,
			<14062 21586 20463 15317 16424 15679>,
			<14128 21801 21899 15388 16037 15790>,
			<14320 22115 23156 15618 15495 15964>,
			<14402 22366 23455 16515 15493 16034>,
			<14470 22771 23519 20380 15960 16055>,
			<14510 23184 23563 23173 16700 16194>,
			<14248 23563 23531 23151 19379 18433>,
			<13661 23903 23427 22918 22689 21378>,
			<13207 23059 23370 22585 23092 21865>,
			<12806 17091 23357 21807 22355 21883>,
			<12580 12507 23406 21187 21574 21879>,
			<12591 12214 23763 21628 20515 20966>,
			<12626 12087 24214 22709 19272 19353>,
			<12656 12066 23435 23043 18769 18243>,
			<12752 12166 20814 22623 18465 17293>,
			<12876 12325 19606 22243 18386 16931>,
			<13037 12693 19961 22677 19248 17117>,
			<13245 13212 20371 23734 20712 17510>,
			<13357 13503 20653 24402 21867 18452>,
			<13424 13731 21274 24803 22950 20672>,
			<13441 13960 21787 25039 23386 21913>,
			<13324 14211 21949 24896 23141 21781>,
			<13114 14467 21984 24328 22691 21389>,
			<13038 14622 22052 23696 22212 21104>,
			<13094 14780 22132 22601 21516 20784>,
			<13164 14859 22134 21441 20848 20444>,
			<13146 14548 21967 20313 20270 19963>,
			<13079 14189 21290 19484 20038 19860>,
			<13355 13949 18521 19483 21138 21032>,
			<13661 13760 16714 19787 21502 19677>,
			<13903 13774 14713 19306 19032 19299>,
			<14076 13501 14508 20133 19073 19189>,
			<14069 13803 14576 19060 19414 18566>,
			<14402 14392 14598 18838 19336 18069>,
			<14868 14426 14807 19785 18977 17020>,
			<14619 14591 14819 19294 19427 19369>,
			<14260 14466 14516 19702 19912 19745>,
			<13819 13822 14463 21292 22674 20475>,
			<12899 13629 14215 22241 24875 25620>,
			<12899 13629 14215 22241 24875 25620>,
			<12899 13629 14215 22241 24875 25620>;
	};

	qcom,pc-temp-y6-lut {
		qcom,lut-col-legend = <(-10) 0 10 25 40 50>;
		qcom,lut-row-legend = <10000 9800 9600 9400 9200 9000>,
			<8800 8600 8400 8200 8000 7800>,
			<7600 7400 7200 7000 6800 6600>,
			<6400 6200 6000 5800 5600 5400>,
			<5200 5000 4800 4600 4400 4200>,
			<4000 3800 3600 3400 3200 3000>,
			<2800 2600 2400 2200 2000 1800>,
			<1600 1400 1200 1000 900 800>,
			<700 600 500 400 300 200>,
			<100 0>;
		qcom,lut-data = <6419 5698 5294 5074 5023 5011>,
			<6369 5699 5297 5074 5023 5012>,
			<6320 5697 5298 5074 5023 5012>,
			<6274 5693 5298 5074 5023 5012>,
			<6234 5688 5297 5074 5023 5013>,
			<6202 5681 5296 5074 5024 5013>,
			<6181 5673 5293 5074 5024 5014>,
			<6162 5663 5288 5075 5025 5015>,
			<6136 5652 5284 5076 5026 5015>,
			<6094 5637 5281 5077 5027 5016>,
			<6067 5629 5280 5079 5029 5017>,
			<6066 5641 5281 5081 5030 5019>,
			<6067 5660 5282 5083 5032 5020>,
			<6054 5656 5284 5086 5034 5021>,
			<5978 5609 5285 5090 5036 5023>,
			<5916 5571 5286 5093 5039 5025>,
			<5906 5563 5282 5099 5042 5027>,
			<5900 5558 5272 5106 5046 5031>,
			<5895 5550 5262 5111 5051 5035>,
			<5890 5539 5246 5115 5060 5042>,
			<5885 5528 5232 5117 5064 5046>,
			<5878 5519 5220 5103 5052 5037>,
			<5871 5512 5211 5075 5034 5023>,
			<5870 5504 5207 5066 5026 5016>,
			<5874 5494 5204 5063 5022 5012>,
			<5881 5489 5203 5062 5020 5011>,
			<5890 5495 5203 5063 5021 5011>,
			<5902 5509 5203 5065 5022 5012>,
			<5916 5523 5202 5066 5023 5013>,
			<5933 5539 5201 5068 5025 5015>,
			<5952 5558 5200 5069 5028 5018>,
			<5973 5579 5204 5072 5032 5021>,
			<5995 5603 5212 5074 5036 5024>,
			<6019 5628 5220 5076 5037 5026>,
			<6045 5657 5231 5077 5037 5027>,
			<6072 5688 5244 5078 5037 5027>,
			<6099 5723 5260 5078 5032 5022>,
			<6127 5760 5278 5077 5026 5015>,
			<6155 5799 5298 5077 5025 5014>,
			<6185 5839 5319 5079 5026 5015>,
			<6215 5879 5343 5081 5027 5017>,
			<6247 5917 5370 5085 5028 5019>,
			<6282 5954 5398 5090 5029 5019>,
			<6322 5994 5426 5094 5026 5015>,
			<6371 6044 5461 5099 5025 5013>,
			<6390 6071 5472 5101 5028 5018>,
			<6402 6094 5501 5106 5034 5026>,
			<6454 6145 5542 5114 5043 5037>,
			<6508 6193 5588 5126 5055 5048>,
			<6569 6241 5642 5140 5057 5045>,
			<6626 6286 5685 5133 5039 5025>,
			<6707 6334 5742 5137 5036 5024>,
			<6825 6415 5860 5165 5043 5028>,
			<7207 6531 6012 5201 5056 5039>,
			<7207 6531 6012 5201 5056 5039>,
			<7207 6531 6012 5201 5056 5039>;
	};

};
